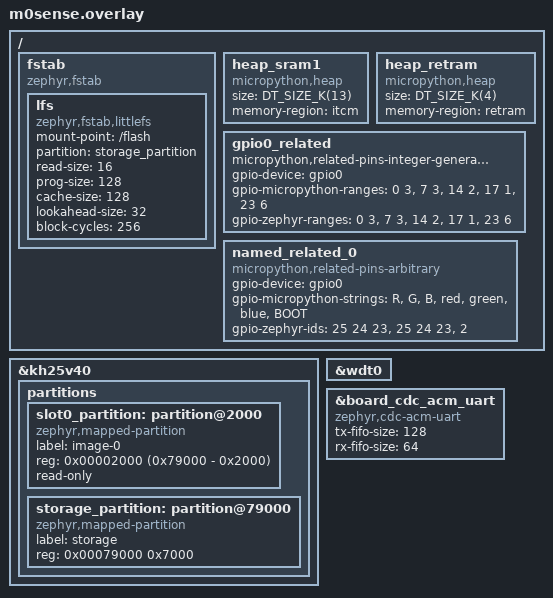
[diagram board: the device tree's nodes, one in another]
/*
 * Copyright (c) 2026 MASSDRIVER EI (massdriver.space)
 *
 * SPDX-License-Identifier: Apache-2.0
 */

/ {
	fstab {
		compatible = "zephyr,fstab";
		lfs: lfs {
			compatible = "zephyr,fstab,littlefs";
			mount-point = "/flash";
			partition = <&storage_partition>;
			read-size=<16>;
			prog-size=<128>;
			cache-size=<128>;
			lookahead-size=<32>;
			block-cycles=<256>;
		};
	};

	heap_sram1 {
		compatible = "micropython,heap";
		size = <DT_SIZE_K(13)>;
		memory-region = <&itcm>;
	};

	heap_retram {
		compatible = "micropython,heap";
		size = <DT_SIZE_K(4)>;
		memory-region = <&retram>;
	};

	gpio0_related {
		compatible = "micropython,related-pins-integer-generator";
		gpio-device = <&gpio0>;
		gpio-micropython-ranges = <0 3>, <7 3>, <14 2>, <17 1>, <23 6>;
		gpio-zephyr-ranges = <0 3>, <7 3>, <14 2>, <17 1>, <23 6>;
	};

	named_related_0 {
		compatible = "micropython,related-pins-arbitrary";
		gpio-device = <&gpio0>;
		gpio-micropython-strings = "R", "G", "B", "red", "green", "blue", "BOOT";
		gpio-zephyr-ids = <25 24 23>, <25 24 23>, <2>;
	};
};

/delete-node/ &slot0_partition;
/delete-node/ &storage_partition;

&kh25v40 {
	partitions {
		ranges;
		#address-cells = <1>;
		#size-cells = <1>;

		slot0_partition: partition@2000 {
			compatible = "zephyr,mapped-partition";
			label = "image-0";
			reg = <0x00002000 (0x79000 - 0x2000)>;
			read-only;
		};

		storage_partition: partition@79000 {
			compatible = "zephyr,mapped-partition";
			label = "storage";
			reg = <0x00079000 0x7000>;
		};
	};
};

&wdt0 {
	status = "okay";
};

&board_cdc_acm_uart {
	compatible = "zephyr,cdc-acm-uart";
	tx-fifo-size = <128>;
	rx-fifo-size = <64>;
};
